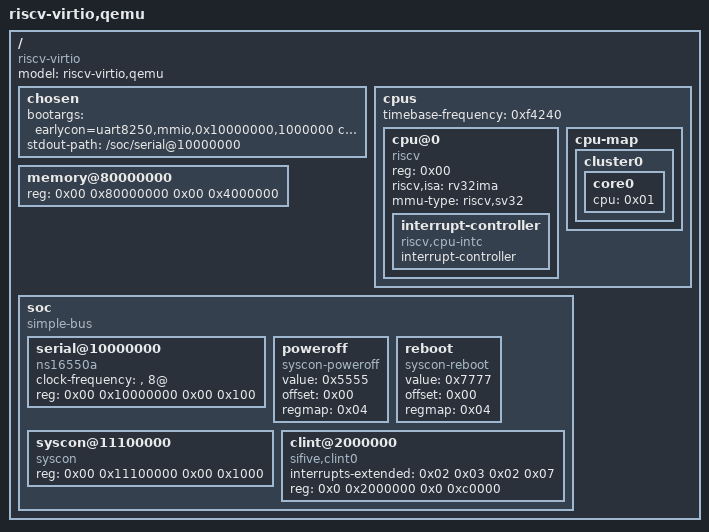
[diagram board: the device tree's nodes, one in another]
/dts-v1/;

/ {
	#address-cells = <0x02>;
	#size-cells = <0x02>;
	compatible = "riscv-virtio";
	model = "riscv-virtio,qemu";

	chosen {
		bootargs = "earlycon=uart8250,mmio,0x10000000,1000000 console=ttyS0";
		stdout-path = "/soc/serial@10000000";
	};

	cpus {
		#address-cells = <0x01>;
		#size-cells = <0x00>;
		timebase-frequency = <0xf4240>;

		cpu@0 {
			phandle = <0x01>;
			device_type = "cpu";
			reg = <0x00>;
			status = "okay";
			compatible = "riscv";
		    riscv,isa = "rv32ima";
			mmu-type = "riscv,sv32";

			interrupt-controller {
				#interrupt-cells = <0x01>;
				interrupt-controller;
				compatible = "riscv,cpu-intc";
				phandle = <0x02>;
			};
		};

		cpu-map {

			cluster0 {

				core0 {
					cpu = <0x01>;
				};
			};
		};
	};

	memory@80000000 {
		device_type = "memory";
		reg = <0x00 0x80000000 0x00 0x4000000>;
	};

	soc {
		#address-cells = <0x02>;
		#size-cells = <0x02>;
		compatible = "simple-bus";
		ranges;

		serial@10000000 {
			clock-frequency = "", "8@";
			reg = <0x00 0x10000000 0x00 0x100>;
			compatible = "ns16550a";
		};

		poweroff {
			value = <0x5555>;
			offset = <0x00>;
			regmap = <0x04>;
			compatible = "syscon-poweroff";
		};

		reboot {
			value = <0x7777>;
			offset = <0x00>;
			regmap = <0x04>;
			compatible = "syscon-reboot";
		};

		syscon@11100000 {
			phandle = <0x04>;
			reg = <0x00 0x11100000 0x00 0x1000>;
			compatible = "syscon";
		};

		clint@2000000 {
			interrupts-extended = <0x02 0x03 0x02 0x07>;
			reg = <0x0 0x2000000   0x0  0xc0000>;
			compatible = "sifive,clint0\0riscv,clint0";
		};
	};
};
